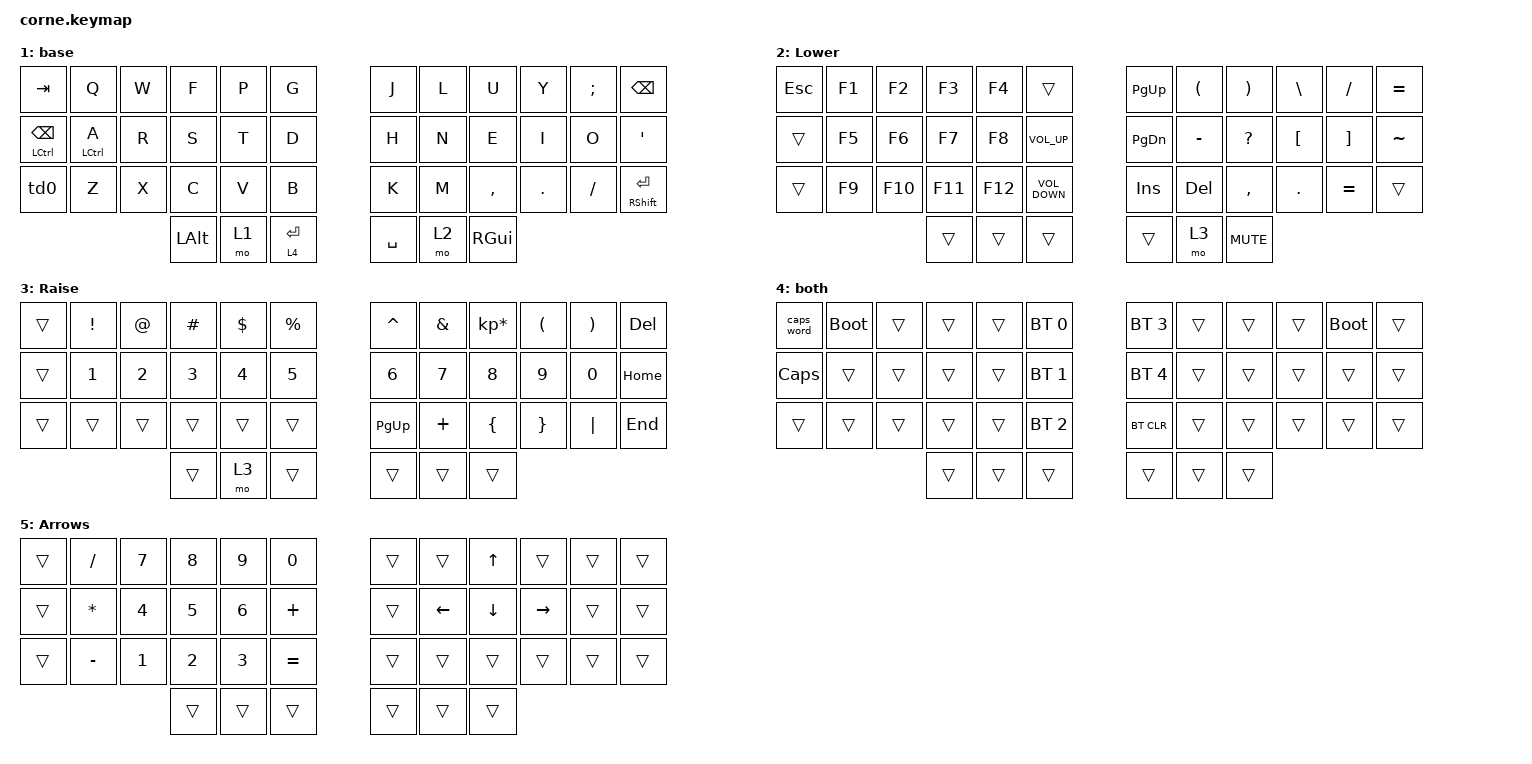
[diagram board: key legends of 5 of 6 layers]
/*
 * Copyright (c) 2020 The ZMK Contributors
 *
 * SPDX-License-Identifier: MIT
 */

#include <behaviors.dtsi>
#include <dt-bindings/zmk/keys.h>
#include <dt-bindings/zmk/bt.h>

/ {
  behaviors {
    td0: tap_dance_0 {
      compatible = "zmk,behavior-tap-dance";
      label = "TAP_DANCE_0";
      #binding-cells = <0>;
      tapping-term-ms = <200>;
      bindings =
        <&kp N1>,
        <&kp N2>,
        <&kp N3>;
    };
  };

  keymap {
    compatible = "zmk,keymap";

    default_layer {
      bindings = <
                &td0
      >;
    };
  };
};

// dt-formatter: indent = "  "
// dt-formatter: reindentMultilineIntegerCells = "dedent"

/ {
  behaviors {
    hm: homerow_mods {
      compatible = "zmk,behavior-hold-tap";
      label = "HOMEROW_MODS";
      #binding-cells = <2>;
      tapping-term-ms = <150>;
      quick-tap-ms = <0>;
      flavor = "tap-preferred";
      bindings =
        <&kp>,
        <&kp>;
    };
  };

  combos {
    compatible = "zmk,combos";

    tab {
      bindings = <&trans>;
      key-positions = <0 12 24 36 41>;
    };

    ctrl {
      bindings = <&kp LCTRL>;
      key-positions = <37 36>;
    };

    cmd {
      bindings = <&kp LCMD>;
      key-positions = <37 38>;
    };

    alt {
      bindings = <&kp LEFT_ALT>;
      key-positions = <39 40>;
    };

    shift {
      bindings = <&kp LSHIFT>;
      key-positions = <8 9>;
    };

    caps_word {
      bindings = <&caps_word>;
      key-positions = <17 18>;
    };

    delete {
      bindings = <&kp DEL>;
      key-positions = <32 33>;
    };

    gui {
      bindings = <&kp LEFT_GUI>;
      key-positions = <36 41>;
    };

    new_combo {
      bindings = <&kp ESC>;
      key-positions = <38 0>;
    };
  };

  macros {
    zed_em_kay: zed_em_kay {
      compatible = "zmk,behavior-macro";
      label = "ZM_zed_em_kay";
      #binding-cells = <0>;
      bindings =
        <&macro_press>,
        <&kp LSHFT>,
        <&macro_tap>,
        <&kp Z &kp M &kp K>,
        <&macro_release>,
        <&kp LSHFT>;
    };
    new_macro: new_macro {
      compatible = "zmk,behavior-macro";
      label = "new_macro";
      #binding-cells = <0>;
      bindings =
        <&macro_press>,
        <&kp>;
    };
  };

  keymap {
    compatible = "zmk,keymap";

    base {
      bindings = <
                    &kp TAB               &kp Q   &kp W         &kp F   &kp P        &kp G              &kp J   &kp L          &kp U    &kp Y  &kp SEMI          &kp BACKSPACE
 &mt LEFT_CONTROL BACKSPACE  &hm LEFT_CONTROL A   &kp R         &kp S   &kp T        &kp D              &kp H   &kp N          &kp E    &kp I     &kp O               &kp APOS
                       &td0               &kp Z   &kp X         &kp C   &kp V        &kp B              &kp K   &kp M      &kp COMMA  &kp DOT  &kp FSLH  &mt RIGHT_SHIFT ENTER
                                                         &kp LEFT_ALT   &mo 1  &lt 4 ENTER          &kp SPACE   &mo 2  &kp RIGHT_GUI
      >;
    };

    Lower {
      bindings = <
 &kp ESC  &kp F1   &kp F2   &kp F3   &kp F4             &trans            &kp PAGE_UP    &kp LPAR      &kp RPAR  &kp BACKSLASH  &kp SLASH  &kp EQUAL
  &trans  &kp F5   &kp F6   &kp F7   &kp F8    &kp C_VOLUME_UP          &kp PAGE_DOWN   &kp MINUS  &kp QUESTION       &kp LBKT   &kp RBKT  &kp TILDE
  &trans  &kp F9  &kp F10  &kp F11  &kp F12  &kp C_VOLUME_DOWN                &kp INS  &kp DELETE     &kp COMMA     &kp PERIOD  &kp EQUAL     &trans
                            &trans   &trans             &trans                 &trans       &mo 3    &kp K_MUTE
      >;
    };

    Raise {
      bindings = <
 &trans      &kp EXCL        &kp AT      &kp HASH      &kp DLLR     &kp PRCNT             &kp CARET      &kp AMPS  &kp KP_MULTIPLY      &kp LPAR      &kp RPAR  &kp DELETE
 &trans  &kp NUMBER_1  &kp NUMBER_2  &kp NUMBER_3  &kp NUMBER_4  &kp NUMBER_5          &kp NUMBER_6  &kp NUMBER_7     &kp NUMBER_8  &kp NUMBER_9  &kp NUMBER_0    &kp HOME
 &trans        &trans        &trans        &trans        &trans        &trans           &kp PAGE_UP      &kp PLUS         &kp LBRC      &kp RBRC      &kp PIPE     &kp END
                                           &trans         &mo 3        &trans                &trans        &trans           &trans
      >;
    };

    both {
      bindings = <
 &caps_word  &bootloader  &trans  &trans  &trans  &bt BT_SEL 0          &bt BT_SEL 3  &trans  &trans  &trans  &bootloader  &trans
   &kp CAPS       &trans  &trans  &trans  &trans  &bt BT_SEL 1          &bt BT_SEL 4  &trans  &trans  &trans       &trans  &trans
     &trans       &trans  &trans  &trans  &trans  &bt BT_SEL 2            &bt BT_CLR  &trans  &trans  &trans       &trans  &trans
                                  &trans  &trans        &trans                &trans  &trans  &trans
      >;
    };

    Arrows {
      bindings = <
 &trans  &kp SLASH  &kp NUMBER_7  &kp NUMBER_8  &kp NUMBER_9  &kp NUMBER_0          &trans    &trans    &kp UP     &trans  &trans  &trans
 &trans  &kp ASTRK  &kp NUMBER_4  &kp NUMBER_5  &kp NUMBER_6      &kp PLUS          &trans  &kp LEFT  &kp DOWN  &kp RIGHT  &trans  &trans
 &trans  &kp MINUS  &kp NUMBER_1  &kp NUMBER_2  &kp NUMBER_3     &kp EQUAL          &trans    &trans    &trans     &trans  &trans  &trans
                                        &trans        &trans        &trans          &trans    &trans    &trans
      >;
    };
  };
};
